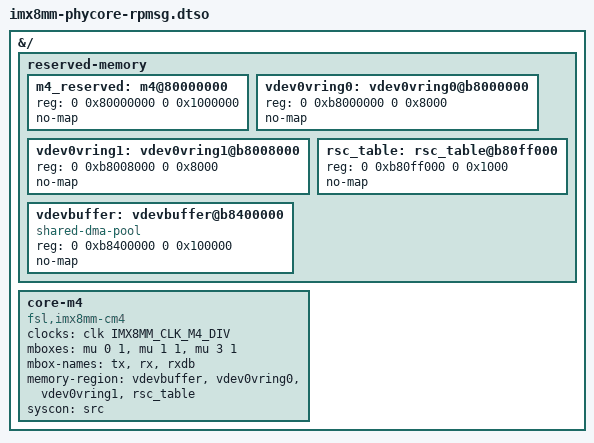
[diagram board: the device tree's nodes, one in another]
// SPDX-License-Identifier: GPL-2.0
/*
 * Copyright (C) 2025 PHYTEC Messtechnik GmbH
 * Author: Dominik Haller <d.haller@phytec.de>
 */

/dts-v1/;
/plugin/;

#include <dt-bindings/clock/imx8mm-clock.h>

&{/} {
	#address-cells = <2>;
	#size-cells = <2>;

	reserved-memory {
		#address-cells = <2>;
		#size-cells = <2>;
		ranges;

		m4_reserved: m4@80000000 {
			reg = <0 0x80000000 0 0x1000000>;
			no-map;
		};

		vdev0vring0: vdev0vring0@b8000000 {
			reg = <0 0xb8000000 0 0x8000>;
			no-map;
		};

		vdev0vring1: vdev0vring1@b8008000 {
			reg = <0 0xb8008000 0 0x8000>;
			no-map;
		};

		rsc_table: rsc_table@b80ff000 {
			reg = <0 0xb80ff000 0 0x1000>;
			no-map;
		};

		vdevbuffer: vdevbuffer@b8400000 {
			compatible = "shared-dma-pool";
			reg = <0 0xb8400000 0 0x100000>;
			no-map;
		};
	};

	core-m4 {
		compatible = "fsl,imx8mm-cm4";
		clocks = <&clk IMX8MM_CLK_M4_DIV>;
		mboxes = <&mu 0 1
			&mu 1 1
			&mu 3 1>;
		mbox-names = "tx", "rx", "rxdb";
		memory-region = <&vdevbuffer>, <&vdev0vring0>, <&vdev0vring1>, <&rsc_table>;
		syscon = <&src>;
	};
};
